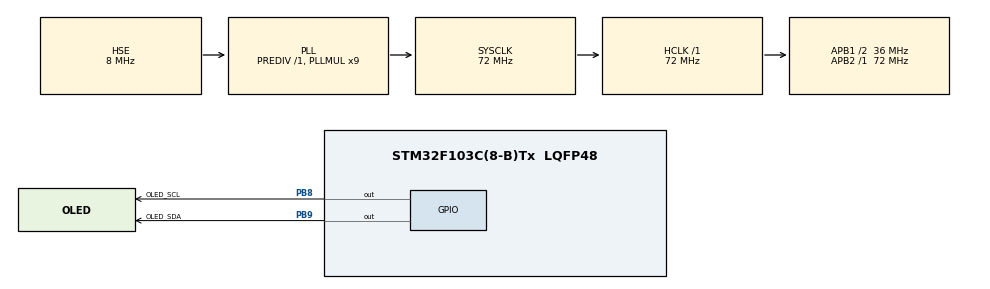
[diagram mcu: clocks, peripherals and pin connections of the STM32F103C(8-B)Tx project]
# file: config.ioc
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FREERTOS.BinarySemaphores01=TIM2Smph,Dynamic,NULL,Depleted
FREERTOS.Events01=TIM1EvtFlag,Dynamic,NULL
FREERTOS.Queues01=SwTmr2Queue,5,uint8_t,0,Dynamic,NULL,NULL
FREERTOS.Tasks01=TaskSwTmr1,48,128,StartTaskSwTmr1,As weak,NULL,Dynamic,NULL,NULL;TaskSwTmr2,40,128,StartTaskSwTmr2,As weak,NULL,Dynamic,NULL,NULL;TaskTIM1,24,128,StartTaskTIM1,As weak,NULL,Dynamic,NULL,NULL;TaskTIM2,16,128,StartTaskTIM2,As weak,NULL,Dynamic,NULL,NULL
FREERTOS.Timers01=SwTmr1,SwTmr1Callback,osTimerOnce,As weak,NULL,Dynamic,NULL;SwTmr2,SwTmr2Callback,osTimerPeriodic,As weak,NULL,Dynamic,NULL
FREERTOS.configGENERATE_RUN_TIME_STATS=1
FREERTOS.configRECORD_STACK_HIGH_ADDRESS=1
FREERTOS.configUSE_STATS_FORMATTING_FUNCTIONS=1
Mcu.Family=STM32F1
Mcu.Name=STM32F103C(8-B)Tx
Mcu.Package=LQFP48
NVIC.PriorityGroup=NVIC_PRIORITYGROUP_4
NVIC.TIM1_UP_IRQn=true\:5\:0\:false\:false\:true\:true\:true\:true\:true
NVIC.TIM2_IRQn=true\:5\:0\:false\:false\:true\:true\:true\:true\:true
NVIC.TIM4_IRQn=true\:15\:0\:false\:false\:true\:false\:false\:true\:true
NVIC.TimeBase=TIM4_IRQn
NVIC.TimeBaseIP=TIM4
PA13.Mode=Serial_Wire
PA13.Signal=SYS_JTMS-SWDIO
PA14.Mode=Serial_Wire
PA14.Signal=SYS_JTCK-SWCLK
PB8.GPIO_Label=OLED_SCL
PB8.GPIO_ModeDefaultOutputPP=GPIO_MODE_OUTPUT_OD
PB8.GPIO_PuPd=GPIO_NOPULL
PB8.GPIO_Speed=GPIO_SPEED_FREQ_HIGH
PB8.PinState=GPIO_PIN_SET
PB8.Signal=GPIO_Output
PB9.GPIO_Label=OLED_SDA
PB9.GPIO_ModeDefaultOutputPP=GPIO_MODE_OUTPUT_OD
PB9.GPIO_PuPd=GPIO_NOPULL
PB9.GPIO_Speed=GPIO_SPEED_FREQ_HIGH
PB9.PinState=GPIO_PIN_SET
PB9.Signal=GPIO_Output
PD0-OSC_IN.Mode=HSE-External-Oscillator
PD0-OSC_IN.Signal=RCC_OSC_IN
PD1-OSC_OUT.Mode=HSE-External-Oscillator
PD1-OSC_OUT.Signal=RCC_OSC_OUT
ProjectManager.HeapSize=0x200
ProjectManager.StackSize=0x400
ProjectManager.TargetToolchain=CMake
RCC.AHBFreq_Value=72000000
RCC.APB1CLKDivider=RCC_HCLK_DIV2
RCC.APB1Freq_Value=36000000
RCC.APB1TimFreq_Value=72000000
RCC.APB2Freq_Value=72000000
RCC.APB2TimFreq_Value=72000000
RCC.HCLKFreq_Value=72000000
RCC.PLLMUL=RCC_PLL_MUL9
RCC.PLLSourceVirtual=RCC_PLLSOURCE_HSE
RCC.SYSCLKFreq_VALUE=72000000
RCC.SYSCLKSource=RCC_SYSCLKSOURCE_PLLCLK
RCC.USBFreq_Value=72000000
TIM1.Period=10000-1
TIM1.Prescaler=14400-1
TIM2.AutoReloadPreload=TIM_AUTORELOAD_PRELOAD_ENABLE
TIM2.Period=10000-1
TIM2.Prescaler=36000-1
VP_FREERTOS_VS_CMSIS_V2.Mode=CMSIS_V2
VP_SYS_VS_tim4.Mode=TIM4
VP_TIM1_VS_ClockSourceINT.Mode=Internal
VP_TIM2_VS_ClockSourceINT.Mode=Internal
board=custom

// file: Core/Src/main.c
/* USER CODE BEGIN Header */
/**
  ******************************************************************************
  * @file           : main.c
  * @brief          : Main program body
  ******************************************************************************
  * @attention
  *
  * Copyright (c) 2026 STMicroelectronics.
  * All rights reserved.
  *
  * This software is licensed under terms that can be found in the LICENSE file
  * in the root directory of this software component.
  * If no LICENSE file comes with this software, it is provided AS-IS.
  *
  ******************************************************************************
  */
/* USER CODE END Header */
#include "main.h"
#include "cmsis_os.h"
#include "cmsis_os2.h"
#include "tim.h"
#include "gpio.h"

void SystemClock_Config(void);
void MX_FREERTOS_Init(void);

int main(void)
{

  /* MCU Configuration--------------------------------------------------------*/

  /* Reset of all peripherals, Initializes the Flash interface and the Systick. */
  HAL_Init();

  /* Configure the system clock */
  SystemClock_Config();

  /* Initialize all configured peripherals */
  MX_GPIO_Init();
  MX_TIM1_Init();
  MX_TIM2_Init();

  /* Init scheduler */
  osKernelInitialize();  /* Call init function for freertos objects (in cmsis_os2.c) */
  MX_FREERTOS_Init();

  /* Start scheduler */
  osKernelStart();

  /* We should never get here as control is now taken by the scheduler */

  /* Infinite loop */
  while (1)
  {

  }
}

void SystemClock_Config(void)
{
  RCC_OscInitTypeDef RCC_OscInitStruct = {0};
  RCC_ClkInitTypeDef RCC_ClkInitStruct = {0};

  /** Initializes the RCC Oscillators according to the specified parameters
  * in the RCC_OscInitTypeDef structure.
  */
  RCC_OscInitStruct.OscillatorType = RCC_OSCILLATORTYPE_HSE;
  RCC_OscInitStruct.HSEState = RCC_HSE_ON;
  RCC_OscInitStruct.HSEPredivValue = RCC_HSE_PREDIV_DIV1;
  RCC_OscInitStruct.HSIState = RCC_HSI_ON;
  RCC_OscInitStruct.PLL.PLLState = RCC_PLL_ON;
  RCC_OscInitStruct.PLL.PLLSource = RCC_PLLSOURCE_HSE;
  RCC_OscInitStruct.PLL.PLLMUL = RCC_PLL_MUL9;
  if (HAL_RCC_OscConfig(&RCC_OscInitStruct) != HAL_OK)
  {
    Error_Handler();
  }

  /** Initializes the CPU, AHB and APB buses clocks
  */
  RCC_ClkInitStruct.ClockType = RCC_CLOCKTYPE_HCLK|RCC_CLOCKTYPE_SYSCLK
                              |RCC_CLOCKTYPE_PCLK1|RCC_CLOCKTYPE_PCLK2;
  RCC_ClkInitStruct.SYSCLKSource = RCC_SYSCLKSOURCE_PLLCLK;
  RCC_ClkInitStruct.AHBCLKDivider = RCC_SYSCLK_DIV1;
  RCC_ClkInitStruct.APB1CLKDivider = RCC_HCLK_DIV2;
  RCC_ClkInitStruct.APB2CLKDivider = RCC_HCLK_DIV1;

  if (HAL_RCC_ClockConfig(&RCC_ClkInitStruct, FLASH_LATENCY_2) != HAL_OK)
  {
    Error_Handler();
  }
}

void HAL_TIM_PeriodElapsedCallback(TIM_HandleTypeDef *htim)
{
  /* USER CODE BEGIN Callback 0 */
  if (htim->Instance == TIM1)
  {
    osEventFlagsSet(TIM1EvtFlagHandle, 0x01);
    HAL_TIM_Base_Start_IT(&htim1);
  }
  else if (htim->Instance == TIM2)
  {
    osSemaphoreRelease(TIM2SmphHandle);
  }
  /* USER CODE END Callback 0 */
  if (htim->Instance == TIM4)
  {
    HAL_IncTick();
  }
}

void Error_Handler(void)
{
  __disable_irq();
  while (1)
  {
  }
}

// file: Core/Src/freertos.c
/* USER CODE BEGIN Header */
/**
 ******************************************************************************
 * File Name          : freertos.c
 * Description        : Code for freertos applications
 ******************************************************************************
 * @attention
 *
 * Copyright (c) 2026 STMicroelectronics.
 * All rights reserved.
 *
 * This software is licensed under terms that can be found in the LICENSE file
 * in the root directory of this software component.
 * If no LICENSE file comes with this software, it is provided AS-IS.
 *
 ******************************************************************************
 */
/* USER CODE END Header */

#include "FreeRTOS.h"
#include "task.h"
#include "main.h"
#include "cmsis_os.h"

/* USER CODE BEGIN Includes */
#include "OLED.h"
/* USER CODE END Includes */

/* Definitions for TaskSwTmr1 */
osThreadId_t TaskSwTmr1Handle;
const osThreadAttr_t TaskSwTmr1_attributes = {
  .name = "TaskSwTmr1",
  .stack_size = 128 * 4,
  .priority = (osPriority_t) osPriorityRealtime,
};
/* Definitions for TaskSwTmr2 */
osThreadId_t TaskSwTmr2Handle;
const osThreadAttr_t TaskSwTmr2_attributes = {
  .name = "TaskSwTmr2",
  .stack_size = 128 * 4,
  .priority = (osPriority_t) osPriorityHigh,
};
/* Definitions for TaskTIM1 */
osThreadId_t TaskTIM1Handle;
const osThreadAttr_t TaskTIM1_attributes = {
  .name = "TaskTIM1",
  .stack_size = 128 * 4,
  .priority = (osPriority_t) osPriorityNormal,
};
/* Definitions for TaskTIM2 */
osThreadId_t TaskTIM2Handle;
const osThreadAttr_t TaskTIM2_attributes = {
  .name = "TaskTIM2",
  .stack_size = 128 * 4,
  .priority = (osPriority_t) osPriorityBelowNormal,
};
/* Definitions for SwTmr2Queue */
osMessageQueueId_t SwTmr2QueueHandle;
const osMessageQueueAttr_t SwTmr2Queue_attributes = {
  .name = "SwTmr2Queue"
};
/* Definitions for SwTmr1 */
osTimerId_t SwTmr1Handle;
const osTimerAttr_t SwTmr1_attributes = {
  .name = "SwTmr1"
};
/* Definitions for SwTmr2 */
osTimerId_t SwTmr2Handle;
const osTimerAttr_t SwTmr2_attributes = {
  .name = "SwTmr2"
};
/* Definitions for TIM2Smph */
osSemaphoreId_t TIM2SmphHandle;
const osSemaphoreAttr_t TIM2Smph_attributes = {
  .name = "TIM2Smph"
};
/* Definitions for TIM1EvtFlag */
osEventFlagsId_t TIM1EvtFlagHandle;
const osEventFlagsAttr_t TIM1EvtFlag_attributes = {
  .name = "TIM1EvtFlag"
};

void StartTaskSwTmr1(void *argument);
void StartTaskSwTmr2(void *argument);
void StartTaskTIM1(void *argument);
void StartTaskTIM2(void *argument);
void SwTmr1Callback(void *argument);
void SwTmr2Callback(void *argument);

void MX_FREERTOS_Init(void); /* (MISRA C 2004 rule 8.1) */

/* Hook prototypes */
void configureTimerForRunTimeStats(void);
unsigned long getRunTimeCounterValue(void);

/* USER CODE BEGIN 1 */
/* Functions needed when configGENERATE_RUN_TIME_STATS is on */
void configureTimerForRunTimeStats(void) {
  /* 1. 使能 TRC (Trace) 模块 */
  CoreDebug->DEMCR |= CoreDebug_DEMCR_TRCENA_Msk;
  /* 2. 重置 DWT 周期计数器 */
  DWT->CYCCNT = 0;
  /* 3. 使能 DWT 周期计数器 */
  DWT->CTRL |= DWT_CTRL_CYCCNTENA_Msk;
}

unsigned long getRunTimeCounterValue(void) {
  return DWT->CYCCNT;
}
/* USER CODE END 1 */

void MX_FREERTOS_Init(void) {

  /* Create the semaphores(s) */
  /* creation of TIM2Smph */
  TIM2SmphHandle = osSemaphoreNew(1, 0, &TIM2Smph_attributes);

  /* Create the timer(s) */
  /* creation of SwTmr1 */
  SwTmr1Handle = osTimerNew(SwTmr1Callback, osTimerOnce, NULL, &SwTmr1_attributes);

  /* creation of SwTmr2 */
  SwTmr2Handle = osTimerNew(SwTmr2Callback, osTimerPeriodic, NULL, &SwTmr2_attributes);

  /* Create the queue(s) */
  /* creation of SwTmr2Queue */
  SwTmr2QueueHandle = osMessageQueueNew (5, sizeof(uint8_t), &SwTmr2Queue_attributes);

  /* Create the thread(s) */
  /* creation of TaskSwTmr1 */
  TaskSwTmr1Handle = osThreadNew(StartTaskSwTmr1, NULL, &TaskSwTmr1_attributes);

  /* creation of TaskSwTmr2 */
  TaskSwTmr2Handle = osThreadNew(StartTaskSwTmr2, NULL, &TaskSwTmr2_attributes);

  /* creation of TaskTIM1 */
  TaskTIM1Handle = osThreadNew(StartTaskTIM1, NULL, &TaskTIM1_attributes);

  /* creation of TaskTIM2 */
  TaskTIM2Handle = osThreadNew(StartTaskTIM2, NULL, &TaskTIM2_attributes);

  /* Create the event(s) */
  /* creation of TIM1EvtFlag */
  TIM1EvtFlagHandle = osEventFlagsNew(&TIM1EvtFlag_attributes);

}

__weak void StartTaskSwTmr1(void *argument)
{
  for(;;)
  {
    osDelay(1);
  }
}

__weak void StartTaskSwTmr2(void *argument)
{
  for(;;)
  {
    osDelay(1);
  }
}

__weak void StartTaskTIM1(void *argument)
{
  for(;;)
  {
    osDelay(1);
  }
}

__weak void StartTaskTIM2(void *argument)
{
  for(;;)
  {
    osDelay(1);
  }
}

/* SwTmr1Callback function */
__weak void SwTmr1Callback(void *argument)
{
}

/* SwTmr2Callback function */
__weak void SwTmr2Callback(void *argument)
{
}
